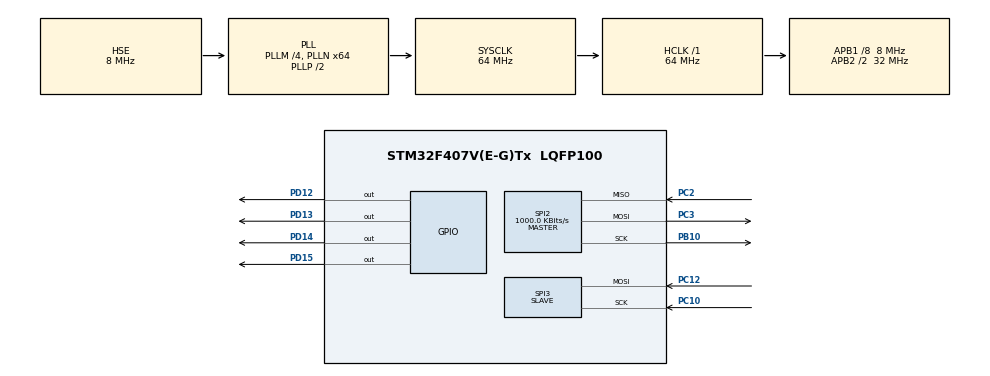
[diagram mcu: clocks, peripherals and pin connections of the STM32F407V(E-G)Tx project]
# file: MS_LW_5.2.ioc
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Mcu.Family=STM32F4
Mcu.Name=STM32F407V(E-G)Tx
Mcu.Package=LQFP100
NVIC.PriorityGroup=NVIC_PRIORITYGROUP_0
NVIC.SPI2_IRQn=true\:0\:0\:true\:false\:true\:true\:true\:true
NVIC.SPI3_IRQn=true\:0\:0\:false\:true\:true\:2\:true\:true\:true
NVIC.TIM3_IRQn=true\:0\:0\:false\:true\:true\:1\:true\:true\:true
PA13.Mode=Trace_Asynchronous_SW
PA13.Signal=SYS_JTMS-SWDIO
PA14.Mode=Trace_Asynchronous_SW
PA14.Signal=SYS_JTCK-SWCLK
PB10.Mode=Full_Duplex_Master
PB10.Signal=SPI2_SCK
PB3.Mode=Trace_Asynchronous_SW
PB3.Signal=SYS_JTDO-SWO
PC10.Mode=RX_Only_Simplex_Unidirect_Slave
PC10.Signal=SPI3_SCK
PC12.Mode=RX_Only_Simplex_Unidirect_Slave
PC12.Signal=SPI3_MOSI
PC2.Mode=Full_Duplex_Master
PC2.Signal=SPI2_MISO
PC3.Mode=Full_Duplex_Master
PC3.Signal=SPI2_MOSI
PD12.Signal=GPIO_Output
PD13.Signal=GPIO_Output
PD14.Signal=GPIO_Output
PD15.Signal=GPIO_Output
PH0-OSC_IN.Mode=HSE-External-Oscillator
PH0-OSC_IN.Signal=RCC_OSC_IN
PH1-OSC_OUT.Mode=HSE-External-Oscillator
PH1-OSC_OUT.Signal=RCC_OSC_OUT
ProjectManager.HeapSize=0x200
ProjectManager.StackSize=0x400
ProjectManager.TargetToolchain=STM32CubeIDE
RCC.48MHZClocksFreq_Value=18285714.285714287
RCC.AHBFreq_Value=64000000
RCC.APB1CLKDivider=RCC_HCLK_DIV8
RCC.APB1Freq_Value=8000000
RCC.APB1TimFreq_Value=16000000
RCC.APB2CLKDivider=RCC_HCLK_DIV2
RCC.APB2Freq_Value=32000000
RCC.APB2TimFreq_Value=64000000
RCC.CortexFreq_Value=64000000
RCC.HCLKFreq_Value=64000000
RCC.HSE_VALUE=8000000
RCC.HSI_VALUE=16000000
RCC.LSE_VALUE=32768
RCC.PLLM=4
RCC.PLLN=64
RCC.PLLQ=7
RCC.PLLSourceVirtual=RCC_PLLSOURCE_HSE
RCC.SYSCLKFreq_VALUE=64000000
RCC.SYSCLKSource=RCC_SYSCLKSOURCE_PLLCLK
RCC.VCOOutputFreq_Value=128000000
SPI2.BaudRatePrescaler=SPI_BAUDRATEPRESCALER_8
SPI2.CalculateBaudRate=1000.0 KBits/s
SPI2.Direction=SPI_DIRECTION_2LINES
SPI2.Mode=SPI_MODE_MASTER
SPI2.VirtualType=VM_MASTER
SPI3.Direction=SPI_DIRECTION_2LINES_RXONLY
SPI3.Mode=SPI_MODE_SLAVE
SPI3.VirtualType=VM_SLAVE
TIM3.Period=1000
TIM3.Prescaler=16000-1
VP_TIM3_VS_ClockSourceINT.Mode=Internal
board=STM32F407G-DISC1

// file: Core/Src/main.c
/* USER CODE BEGIN Header */
/**
  ******************************************************************************
  * @file           : main.c
  * @brief          : Main program body
  ******************************************************************************
  * @attention
  *
  * Copyright (c) 2023 STMicroelectronics.
  * All rights reserved.
  *
  * This software is licensed under terms that can be found in the LICENSE file
  * in the root directory of this software component.
  * If no LICENSE file comes with this software, it is provided AS-IS.
  *
  ******************************************************************************
  */
/* USER CODE END Header */
#include "main.h"

SPI_HandleTypeDef hspi2;
SPI_HandleTypeDef hspi3;

TIM_HandleTypeDef htim3;

/* USER CODE BEGIN PV */
uint8_t buffer_tx[4] = {15, 14, 13, 12};
uint8_t buffer_rx;
/* USER CODE END PV */

void SystemClock_Config(void);
static void MX_GPIO_Init(void);
static void MX_SPI2_Init(void);
static void MX_SPI3_Init(void);
static void MX_TIM3_Init(void);
static void MX_NVIC_Init(void);

/* USER CODE BEGIN 0 */
int temp = 0;
/* USER CODE END 0 */

int main(void)
{

  /* MCU Configuration--------------------------------------------------------*/

  /* Reset of all peripherals, Initializes the Flash interface and the Systick. */
  HAL_Init();

  /* Configure the system clock */
  SystemClock_Config();

  /* Initialize all configured peripherals */
  MX_GPIO_Init();
  MX_SPI2_Init();
  MX_SPI3_Init();
  MX_TIM3_Init();

  /* Initialize interrupts */
  MX_NVIC_Init();
  /* USER CODE BEGIN 2 */
  //HAL_SPI
  HAL_TIM_Base_Start_IT(&htim3);
  /* USER CODE END 2 */

  /* Infinite loop */
   while (1)
  {

  }
}

void SystemClock_Config(void)
{
  RCC_OscInitTypeDef RCC_OscInitStruct = {0};
  RCC_ClkInitTypeDef RCC_ClkInitStruct = {0};

  /** Configure the main internal regulator output voltage
  */
  __HAL_RCC_PWR_CLK_ENABLE();
  __HAL_PWR_VOLTAGESCALING_CONFIG(PWR_REGULATOR_VOLTAGE_SCALE1);

  /** Initializes the RCC Oscillators according to the specified parameters
  * in the RCC_OscInitTypeDef structure.
  */
  RCC_OscInitStruct.OscillatorType = RCC_OSCILLATORTYPE_HSE;
  RCC_OscInitStruct.HSEState = RCC_HSE_ON;
  RCC_OscInitStruct.PLL.PLLState = RCC_PLL_ON;
  RCC_OscInitStruct.PLL.PLLSource = RCC_PLLSOURCE_HSE;
  RCC_OscInitStruct.PLL.PLLM = 4;
  RCC_OscInitStruct.PLL.PLLN = 64;
  RCC_OscInitStruct.PLL.PLLP = RCC_PLLP_DIV2;
  RCC_OscInitStruct.PLL.PLLQ = 7;
  if (HAL_RCC_OscConfig(&RCC_OscInitStruct) != HAL_OK)
  {
    Error_Handler();
  }

  /** Initializes the CPU, AHB and APB buses clocks
  */
  RCC_ClkInitStruct.ClockType = RCC_CLOCKTYPE_HCLK|RCC_CLOCKTYPE_SYSCLK
                              |RCC_CLOCKTYPE_PCLK1|RCC_CLOCKTYPE_PCLK2;
  RCC_ClkInitStruct.SYSCLKSource = RCC_SYSCLKSOURCE_PLLCLK;
  RCC_ClkInitStruct.AHBCLKDivider = RCC_SYSCLK_DIV1;
  RCC_ClkInitStruct.APB1CLKDivider = RCC_HCLK_DIV8;
  RCC_ClkInitStruct.APB2CLKDivider = RCC_HCLK_DIV2;

  if (HAL_RCC_ClockConfig(&RCC_ClkInitStruct, FLASH_LATENCY_2) != HAL_OK)
  {
    Error_Handler();
  }
}

/**
  * @brief NVIC Configuration.
  * @retval None
  */
static void MX_NVIC_Init(void)
{
  /* TIM3_IRQn interrupt configuration */
  HAL_NVIC_SetPriority(TIM3_IRQn, 0, 0);
  HAL_NVIC_EnableIRQ(TIM3_IRQn);
  /* SPI3_IRQn interrupt configuration */
  HAL_NVIC_SetPriority(SPI3_IRQn, 0, 0);
  HAL_NVIC_EnableIRQ(SPI3_IRQn);
}

static void MX_SPI2_Init(void)
{

  /* SPI2 parameter configuration*/
  hspi2.Instance = SPI2;
  hspi2.Init.Mode = SPI_MODE_MASTER;
  hspi2.Init.Direction = SPI_DIRECTION_2LINES;
  hspi2.Init.DataSize = SPI_DATASIZE_8BIT;
  hspi2.Init.CLKPolarity = SPI_POLARITY_LOW;
  hspi2.Init.CLKPhase = SPI_PHASE_1EDGE;
  hspi2.Init.NSS = SPI_NSS_SOFT;
  hspi2.Init.BaudRatePrescaler = SPI_BAUDRATEPRESCALER_8;
  hspi2.Init.FirstBit = SPI_FIRSTBIT_MSB;
  hspi2.Init.TIMode = SPI_TIMODE_DISABLE;
  hspi2.Init.CRCCalculation = SPI_CRCCALCULATION_DISABLE;
  hspi2.Init.CRCPolynomial = 10;
  if (HAL_SPI_Init(&hspi2) != HAL_OK)
  {
    Error_Handler();
  }

}

static void MX_SPI3_Init(void)
{

  /* SPI3 parameter configuration*/
  hspi3.Instance = SPI3;
  hspi3.Init.Mode = SPI_MODE_SLAVE;
  hspi3.Init.Direction = SPI_DIRECTION_2LINES_RXONLY;
  hspi3.Init.DataSize = SPI_DATASIZE_8BIT;
  hspi3.Init.CLKPolarity = SPI_POLARITY_LOW;
  hspi3.Init.CLKPhase = SPI_PHASE_1EDGE;
  hspi3.Init.NSS = SPI_NSS_SOFT;
  hspi3.Init.FirstBit = SPI_FIRSTBIT_MSB;
  hspi3.Init.TIMode = SPI_TIMODE_DISABLE;
  hspi3.Init.CRCCalculation = SPI_CRCCALCULATION_DISABLE;
  hspi3.Init.CRCPolynomial = 10;
  if (HAL_SPI_Init(&hspi3) != HAL_OK)
  {
    Error_Handler();
  }

}

static void MX_TIM3_Init(void)
{

  TIM_ClockConfigTypeDef sClockSourceConfig = {0};
  TIM_MasterConfigTypeDef sMasterConfig = {0};

  htim3.Instance = TIM3;
  htim3.Init.Prescaler = 16000-1;
  htim3.Init.CounterMode = TIM_COUNTERMODE_UP;
  htim3.Init.Period = 1000;
  htim3.Init.ClockDivision = TIM_CLOCKDIVISION_DIV1;
  htim3.Init.AutoReloadPreload = TIM_AUTORELOAD_PRELOAD_DISABLE;
  if (HAL_TIM_Base_Init(&htim3) != HAL_OK)
  {
    Error_Handler();
  }
  sClockSourceConfig.ClockSource = TIM_CLOCKSOURCE_INTERNAL;
  if (HAL_TIM_ConfigClockSource(&htim3, &sClockSourceConfig) != HAL_OK)
  {
    Error_Handler();
  }
  sMasterConfig.MasterOutputTrigger = TIM_TRGO_RESET;
  sMasterConfig.MasterSlaveMode = TIM_MASTERSLAVEMODE_DISABLE;
  if (HAL_TIMEx_MasterConfigSynchronization(&htim3, &sMasterConfig) != HAL_OK)
  {
    Error_Handler();
  }

}

static void MX_GPIO_Init(void)
{
  GPIO_InitTypeDef GPIO_InitStruct = {0};

  /* GPIO Ports Clock Enable */
  __HAL_RCC_GPIOH_CLK_ENABLE();
  __HAL_RCC_GPIOC_CLK_ENABLE();
  __HAL_RCC_GPIOB_CLK_ENABLE();
  __HAL_RCC_GPIOD_CLK_ENABLE();
  __HAL_RCC_GPIOA_CLK_ENABLE();

  /*Configure GPIO pin Output Level */
  HAL_GPIO_WritePin(GPIOD, GPIO_PIN_12|GPIO_PIN_13|GPIO_PIN_14|GPIO_PIN_15, GPIO_PIN_RESET);

  /*Configure GPIO pins : PD12 PD13 PD14 PD15 */
  GPIO_InitStruct.Pin = GPIO_PIN_12|GPIO_PIN_13|GPIO_PIN_14|GPIO_PIN_15;
  GPIO_InitStruct.Mode = GPIO_MODE_OUTPUT_PP;
  GPIO_InitStruct.Pull = GPIO_NOPULL;
  GPIO_InitStruct.Speed = GPIO_SPEED_FREQ_LOW;
  HAL_GPIO_Init(GPIOD, &GPIO_InitStruct);

}

/* USER CODE BEGIN 4 */
/////////////////////////////////////
void HAL_TIM_PeriodElapsedCallback(TIM_HandleTypeDef *htim)
{
  /* USER CODE BEGIN Callback 0 */

  /* USER CODE END Callback 0 */
  if (htim->Instance == TIM3) {
	//  temp += 1;
  }
  /* USER CODE BEGIN Callback 1 */
  //temp = temp + 1;

  /* USER CODE END Callback 1 */
}
/////////////////////////////////
/* USER CODE END 4 */

void Error_Handler(void)
{
  __disable_irq();
  while (1)
  {
  }
}
